# f2838x_cm_udmachdes_regs register map
Vendor: Texas Instruments
Peripheral module from a debugger description file (folder C2000).
Address unit: 16 bits
Registers are 32-bit, read-write, no defined reset value unless marked. A register's access mark holds for its fields unless they carry their own. Offsets are as the file gives them; lines under a group give offsets from that group; [hi:lo] are bit positions; {n}, {i} and the like mark numbered series; 'fields as' and 'values as' point back to an identical list; <NAME> marks a mode.

## UDMACHDES — UDMACHDES Registers
0x00 DMASRCENDP — DMA Channel Source Address End Pointer
  [31:0] ADDR — Source Address End Pointer
0x04 DMADSTENDP — DMA Channel Destination Address End Pointer
  [31:0] ADDR — Destination Address End Pointer
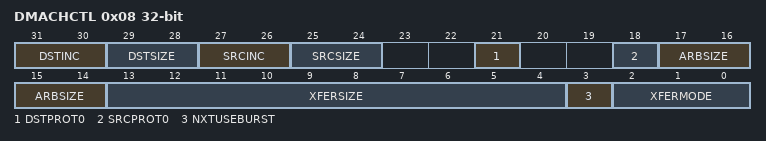
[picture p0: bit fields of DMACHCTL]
0x08 DMACHCTL — DMA Channel Control Word
  [31:30] DSTINC — Destination Address Increment
  [29:28] DSTSIZE — Destination Data Size
  [27:26] SRCINC — Source Address Increment
  [25:24] SRCSIZE — Source Data Size
  [21] DSTPROT0 — Destination Privilege Access
  [18] SRCPROT0 — Source Privilege Access
  [17:14] ARBSIZE — Arbitration Size
  [13:4] XFERSIZE — Transfer Size (minus 1)
  [3] NXTUSEBURST — Next Useburst
  [2:0] XFERMODE — DMA Transfer Mode
